# HC32F467 register map
File version: 1.0
CPU: CM4 r0p1, little endian, MPU, FPU, 4 interrupt priority bits
Registers are 32-bit, read-write, reset 0x0 unless marked. A register's access mark holds for its fields unless they carry their own. Offsets are from the block's base; [hi:lo] are bit positions; {n}, {i} and the like mark numbered series.

## EMB0 — desc EMB
Base 0x40017C00
Same registers: EMB1 0x40017C20, EMB2 0x40017C40, EMB3 0x40017C60, EMB4 0x40017C80, EMB5 0x40017CA0, EMB6 0x40017CC0
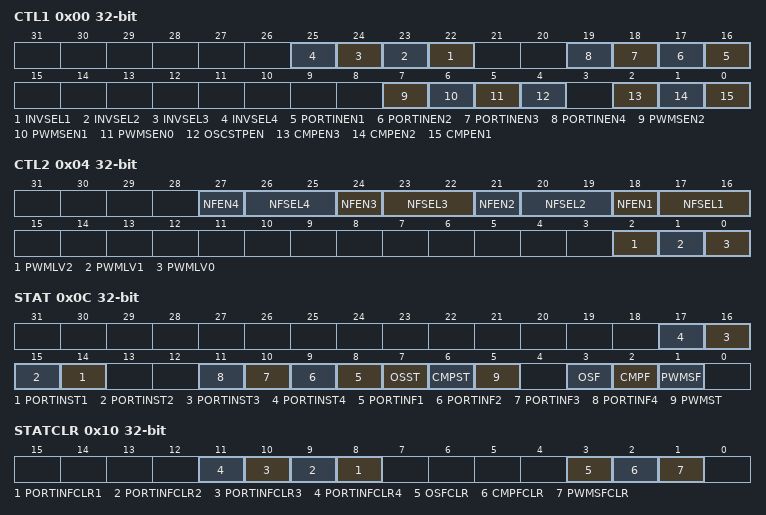
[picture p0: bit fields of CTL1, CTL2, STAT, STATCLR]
0x00 CTL1
  [n+21] INVSEL{n} (n=1..4), [n+15] PORTINEN{n} (n=1..4), [7] PWMSEN2, [6] PWMSEN1, [5] PWMSEN0, [4] OSCSTPEN, [2] CMPEN3, [1] CMPEN2, [0] CMPEN1
0x04 CTL2
  [3n+15] NFEN{n} (n=1..4), [3n+14:3n+13] NFSEL{n} (n=1..4), [2] PWMLV2, [1] PWMLV1, [0] PWMLV0
0x08 SOE
  [0] SOE
0x0C STAT ro
  [n+13] PORTINST{n} (n=1..4), [n+7] PORTINF{n} (n=1..4), [7] OSST, [6] CMPST, [5] PWMST, [3] OSF, [2] CMPF, [1] PWMSF
0x10 STATCLR wo
  [n+7] PORTINFCLR{n} (n=1..4), [3] OSFCLR, [2] CMPFCLR, [1] PWMSFCLR
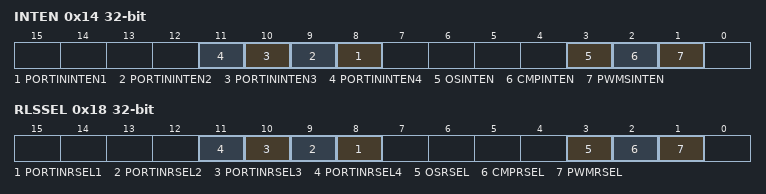
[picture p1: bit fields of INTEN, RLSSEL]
0x14 INTEN
  [n+7] PORTININTEN{n} (n=1..4), [3] OSINTEN, [2] CMPINTEN, [1] PWMSINTEN
0x18 RLSSEL
  [n+7] PORTINRSEL{n} (n=1..4), [3] OSRSEL, [2] CMPRSEL, [1] PWMRSEL

## FCM
Base 0x40048400
0x00 LVR
  [15:0] LVR
0x04 UVR
  [15:0] UVR
0x08 CNTR ro
  [15:0] CNTR
0x0C STR
  [0] START
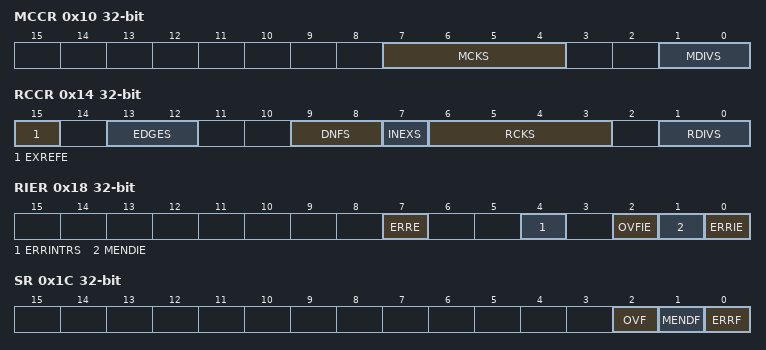
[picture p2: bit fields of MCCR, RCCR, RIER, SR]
0x10 MCCR
  [7:4] MCKS, [1:0] MDIVS
0x14 RCCR
  [15] EXREFE, [13:12] EDGES, [9:8] DNFS, [7] INEXS, [6:3] RCKS, [1:0] RDIVS
0x18 RIER
  [7] ERRE, [4] ERRINTRS, [2] OVFIE, [1] MENDIE, [0] ERRIE
0x1C SR ro
  [2] OVF, [1] MENDF, [0] ERRF
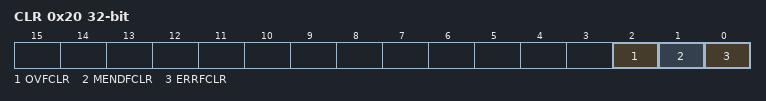
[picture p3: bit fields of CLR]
0x20 CLR wo
  [2] OVFCLR, [1] MENDFCLR, [0] ERRFCLR

## FMAC1 — desc FMAC
Base 0x40058000
Same registers: FMAC2 0x40058400, FMAC3 0x40058800, FMAC4 0x40058C00
0x00 ENR
  [0] FMACEN
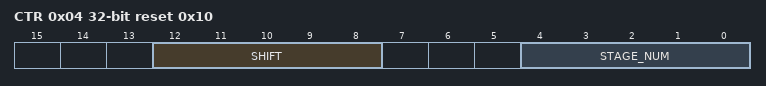
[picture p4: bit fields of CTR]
0x04 CTR reset 0x10
  [12:8] SHIFT, [4:0] STAGE_NUM
0x08 IER
  [0] INTEN
0x0C DTR
  [15:0] DIN
0x10 RTR0
0x14 RTR1
0x18 STR
  [31] READY
{0x20+4i} COR{i} (i=0..16)
  [15:0] CIN

## HASH
Base 0x40008400
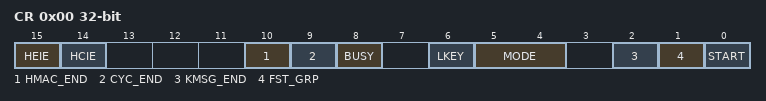
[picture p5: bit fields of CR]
0x00 CR
  [15] HEIE, [14] HCIE, [10] HMAC_END, [9] CYC_END, [8] BUSY, [6] LKEY, [5:4] MODE, [2] KMSG_END, [1] FST_GRP, [0] START
0x10 HR7
0x14 HR6
0x18 HR5
0x1C HR4
0x20 HR3
0x24 HR2
0x28 HR1
0x2C HR0
0x40 DR15
0x44 DR14
0x48 DR13
0x4C DR12
0x50 DR11
0x54 DR10
0x58 DR9
0x5C DR8
0x60 DR7
0x64 DR6
0x68 DR5
0x6C DR4
0x70 DR3
0x74 DR2
0x78 DR1
0x7C DR0

## I2C1 — desc I2C
Base 0x4004E000
Same registers: I2C2 0x4004E400, I2C3 0x4004E800
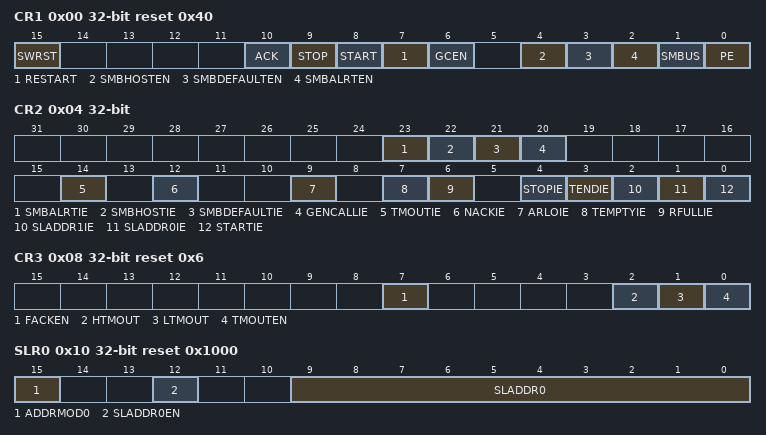
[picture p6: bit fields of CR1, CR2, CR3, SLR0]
0x00 CR1 reset 0x40
  [15] SWRST, [10] ACK, [9] STOP, [8] START, [7] RESTART, [6] GCEN, [4] SMBHOSTEN, [3] SMBDEFAULTEN, [2] SMBALRTEN, [1] SMBUS, [0] PE
0x04 CR2
  [23] SMBALRTIE, [22] SMBHOSTIE, [21] SMBDEFAULTIE, [20] GENCALLIE, [14] TMOUTIE, [12] NACKIE, [9] ARLOIE, [7] TEMPTYIE, [6] RFULLIE, [4] STOPIE, [3] TENDIE, [2] SLADDR1IE, [1] SLADDR0IE, [0] STARTIE
0x08 CR3 reset 0x6
  [7] FACKEN, [2] HTMOUT, [1] LTMOUT, [0] TMOUTEN
0x0C CR4 reset 0x300307
  [10] BUSWAIT
0x10 SLR0 reset 0x1000
  [15] ADDRMOD0, [12] SLADDR0EN, [9:0] SLADDR0
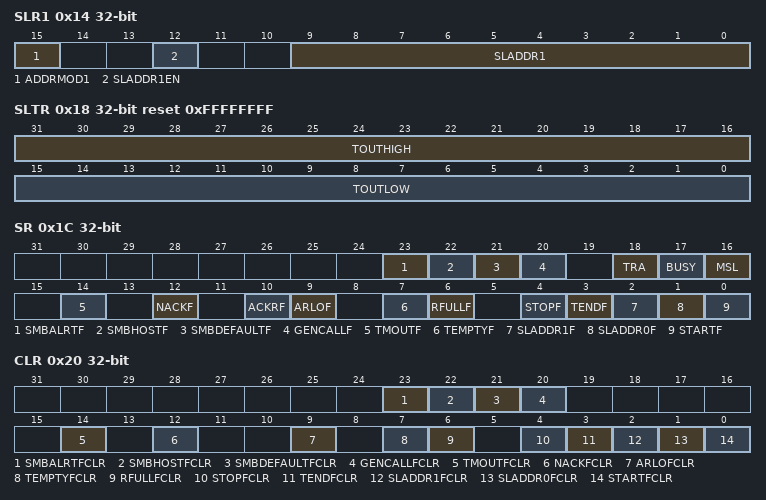
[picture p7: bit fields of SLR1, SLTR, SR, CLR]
0x14 SLR1
  [15] ADDRMOD1, [12] SLADDR1EN, [9:0] SLADDR1
0x18 SLTR reset 0xFFFFFFFF
  [31:16] TOUTHIGH, [15:0] TOUTLOW
0x1C SR
  [23] SMBALRTF, [22] SMBHOSTF, [21] SMBDEFAULTF, [20] GENCALLF, [18] TRA, [17] BUSY, [16] MSL, [14] TMOUTF, [12] NACKF, [10] ACKRF, [9] ARLOF, [7] TEMPTYF, [6] RFULLF, [4] STOPF, [3] TENDF, [2] SLADDR1F, [1] SLADDR0F, [0] STARTF
0x20 CLR wo
  [23] SMBALRTFCLR, [22] SMBHOSTFCLR, [21] SMBDEFAULTFCLR, [20] GENCALLFCLR, [14] TMOUTFCLR, [12] NACKFCLR, [9] ARLOFCLR, [7] TEMPTYFCLR, [6] RFULLFCLR, [4] STOPFCLR, [3] TENDFCLR, [2] SLADDR1FCLR, [1] SLADDR0FCLR, [0] STARTFCLR
0x24 DTR 8-bit wo reset 0xFF
  [7:0] DT
0x28 DRR 8-bit ro
  [7:0] DR
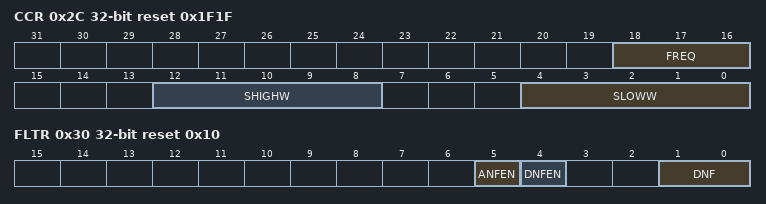
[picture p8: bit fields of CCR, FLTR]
0x2C CCR reset 0x1F1F
  [18:16] FREQ, [12:8] SHIGHW, [4:0] SLOWW
0x30 FLTR reset 0x10
  [5] ANFEN, [4] DNFEN, [1:0] DNF

## I2S1 — desc I2S
Base 0x4001E000
Same registers: I2S2 0x4001E400, I2S3 0x40022000, I2S4 0x40022400
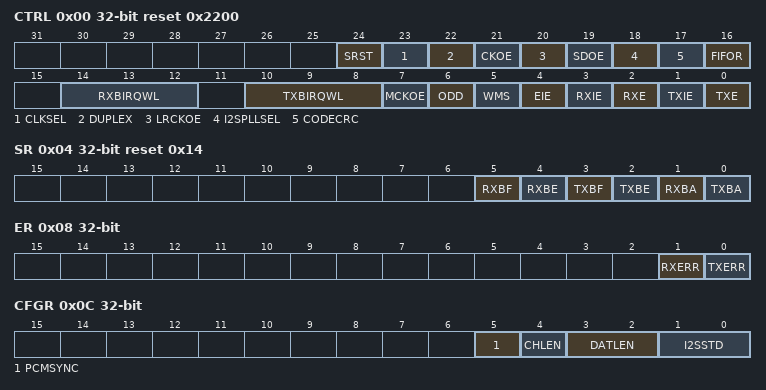
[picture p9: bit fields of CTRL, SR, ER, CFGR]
0x00 CTRL reset 0x2200
  [24] SRST, [23] CLKSEL, [22] DUPLEX, [21] CKOE, [20] LRCKOE, [19] SDOE, [18] I2SPLLSEL, [17] CODECRC, [16] FIFOR, [14:12] RXBIRQWL, [10:8] TXBIRQWL, [7] MCKOE, [6] ODD, [5] WMS, [4] EIE, [3] RXIE, [2] RXE, [1] TXIE, [0] TXE
0x04 SR ro reset 0x14
  [5] RXBF, [4] RXBE, [3] TXBF, [2] TXBE, [1] RXBA, [0] TXBA
0x08 ER
  [1] RXERR, [0] TXERR
0x0C CFGR
  [5] PCMSYNC, [4] CHLEN, [3:2] DATLEN, [1:0] I2SSTD
0x10 TXBUF wo
0x14 RXBUF ro
0x18 PR reset 0x2
  [7:0] I2SDIV
